# FM33A0XXX register map
File version: 1.0
CPU: SC000 r1p0, little endian, MPU, no FPU, 3 interrupt priority bits
Registers are 32-bit, read-write, reset 0x0 unless marked. A register's access mark holds for its fields unless they carry their own. Offsets are from the block's base; [hi:lo] are bit positions.

## PMU — POWER MANAGEMENT UNIT
Base 0x40000100
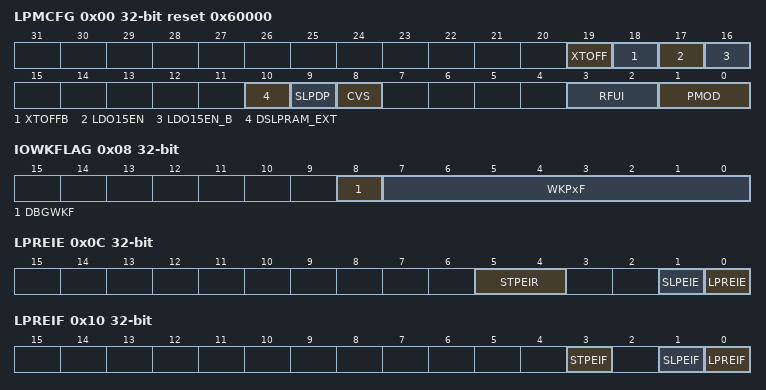
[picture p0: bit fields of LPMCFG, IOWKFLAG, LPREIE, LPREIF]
0x00 LPMCFG ro reset 0x60000 — Low Power Management Config Register
  [19] XTOFF rw — XTOFF BIT
    0=ENABLE (XTLF ENABLE); 1=DISABLE (XTLF DISABLE)
  [18] XTOFFB rw — XTOFFB BIT REVERSE
    0=XTLF CLOSE; 1=XTLF ENABLE
  [17] LDO15EN — LDO15 enable status
    0=DISABLE (LDO15 SHUT DOWN); 1=ENABLE (LDO15 ENABLE)
  [16] LDO15EN_B — LDO15 ENABLE BIT REVERSE
    0=ENABLE (ldo15 enable); 1=shutdown (ldo15 shutdown)
  [10] DSLPRAM_EXT rw — RAM status at deepsleep mode
    0=Alive (ram alive at deepsleep); 1=RAM_SHUTDOWN (RAM shutdown at deepsleep)
  [9] SLPDP rw — DeepSleep config
    0=Sleep mode; 1=DeepSleep mode,close vref
  [8] CVS rw — Core Voltage Scaling
    0=NOScaling (NOT Scaling at Sleep/DeepSleep/Stop mode); 1=Scaling to 1.2V at Sleep/DeepSleep/Stop mode
  [3:2] RFUI rw
  [1:0] PMOD rw — power down mode
    0=Active mode; 1=LPRUN mode; 2=Sleep mode; 3=Stop mode
0x04 WKDLYCON reset 0x1 — Wakeup Delay Control Register
  [1:0] TRHR — TIME OF RHR AT DeepSleep/Stop
    0=12us (time of RHR is 12us); 1=16us (time of RHR is 16us); 2=24us (time of RHR is 24us); 3=32us (time of RHR is 32us)
0x08 IOWKFLAG — IO Wakeup FLAG Register
  [8] DBGWKF — debug wakeup flag,write 1 to clear
    0=NODBWK (no debug wakeup); 1=DBWK (debug wakeup)
  [7:0] WKPxF — wakeup flag of pinX
0x0C LPREIE — low power IE register
  [5:4] STPEIR — stop error interrupt enable bit
    0=DISABLE (disable stop error interupt); 1=ENABLE (stop error interrupt enable)
  [1] SLPEIE — sleep error interrupt enable bit
    0=DISABLE (disable Sleep error interrupt); 1=ENABLE (Enable sleep error interrupt)
  [0] LPREIE — low power run error interrupt enable bit
    0=DISABLE (Disable lprun error interrupt); 1=ENABLE (Enable lprun error interrupt)
0x10 LPREIF — low power interrupt flag register
  [3] STPEIF — go into stop mode error flag
    0=STOP_OK (go into stop mode ok); 1=STOP_ERR (go into stop mode error)
  [1] SLPEIF — go into sleep mode error
    0=SLEEP_OK (go into sleep mode ok); 1=SLEEP_ERR (go into sleep mode error)
  [0] LPREIF — lprun error
    0=LPRUN_OK (go into lprun mode ok); 1=LPRUN_ERR (go into lprun mode error)

## HSPI — High speed SPI
Base 0x40000800
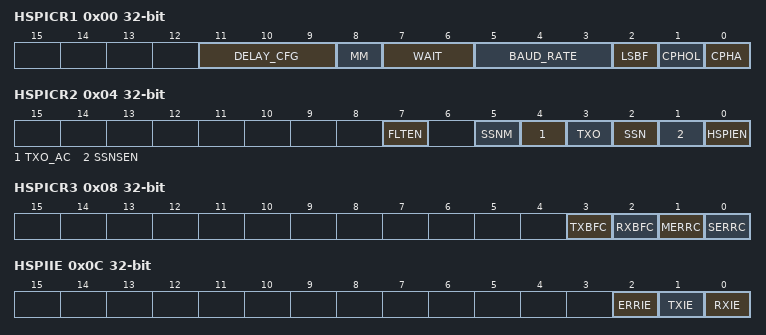
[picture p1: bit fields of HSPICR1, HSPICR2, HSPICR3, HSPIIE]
0x00 HSPICR1 — HSPI Control Register
  [11:9] DELAY_CFG — DELAY time setting for master sample delay /slave sending ahead
    0=NO_DELAY/NO_AHEAD (NO_DELAY at master/NO_AHEAD at slave); 1=10NS/0.5SCK-20NS (10NS delay at master/0.5SCK-20NS ahead at slave); 2=20NS/0.5SCK-15NS (20NS delay at master/0.5SCK-15NS ahead at slave); 3=30NS/0.5SCK-10NS (30NS delay at master/0.5SCK-10NS ahead at slave); 4=40NS/0.5SCK-5NS (40NS delay at master/0.5SCK-5NS ahead at slave); 5=0.5SCK (0.5SCK delay at master/0.5SCK ahead at slave); 6=0.5SCK (0.5SCK delay at master/0.5SCK ahead at slave); 7=0.5SCK (0.5SCK delay at master/0.5SCK ahead at slave)
  [8] MM — Master/Slave mode select
    0=SLAVE (slave mode); 1=Master mode
  [7:6] WAIT — WAIT clock setting at master mode,(1+wait) clock
  [5:3] BAUD_RATE — BAUD_RATE setting
    0=fPCLK (only Master mode); 1=fPCLK/2 (only Master mode); 2=fPCLK/4 (only Master mode); 3=fPCLK/8 (only Master mode); 4=fPCLK/16 (only Master mode); 5=fPCLK/32 (only Master mode); 6=fPCLK/64 (only Master mode); 7=fPCLK/128 (only Master mode)
  [2] LSBF — Frame format bit
    0=MSB (MSB first); 1=LSB (LSB first)
  [1] CPHOL — Clock polarity bit
    0=LOW (Idle clock voltage is low); 1=HIGH (Idle clock voltage is low)
  [0] CPHA — Clock phase bit
    0=FIRST (capture at First edge); 1=SECOND (capture at Second edge)
0x04 HSPICR2 — control Register2
  [7] FLTEN — filter enable for SSN/SCK/MOSI pad
    0=NO_FILTER (no filter for pad input); 1=4NS (filter 4ns for SSN/SCK/MOSI pad)
  [5] SSNM — SSN keep low/high after sending 8bit data at master mode
    0=LOW (SSN keep low after sending 8bit data at master mode); 1=HIGH (SSN keep hign after sending 8bit data at master mode)
  [4] TXO_AC — auto clear at tx_only mode enable
    0=DISABLE (disable auto clear at tx_only mode enable); 1=ENABLE (enable auto clear at tx_only mode enable)
  [3] TXO — TX only
    0=DISABLE (disable tx_only mode); 1=ENABLE (enable tx_only mode)
  [2] SSN — SSN control bit
    0=LOW (SSN output is low voltage); 1=HIGH (SSN output is high voltage)
  [1] SSNSEN — SSN controled by software at master mode
    0=AUTO_OUTPUT (SSN auto output at master mode); 1=SOFTWARE (SSN output controled by software at master mode)
  [0] HSPIEN — HSPI enable bit
    0=DISABLE (HSPI disable); 1=ENABLE (HSPI enable)
0x08 HSPICR3 — control Register3
  [3] TXBFC — Transmit Buffer Clear bit,write 1 to clear
  [2] RXBFC — Receive Buffer Clear bit,write 1 to clear
  [1] MERRC — Master Error Clear bit,write 1 to clear
  [0] SERRC — Slave Error Clear bit,write 1 to clear
0x0C HSPIIE — HSPI interrupt enable Register
  [2] ERRIE — error interrupt enable bit
  [1] TXIE — transmit interrupt enable bit
  [0] RXIE — receive interrupt enable bit
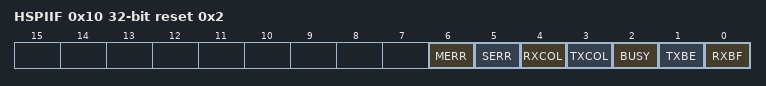
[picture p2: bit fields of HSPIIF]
0x10 HSPIIF reset 0x2 — HSPI interrupt flag Register
  [6] MERR ro — Master Error
  [5] SERR ro — Slave Error
  [4] RXCOL — RX Buffer overflow,write 1 to clear
  [3] TXCOL — TX Buffer overflow,write 1 to clear
  [2] BUSY ro — HSPI transmit flag
  [1] TXBE ro — TX Buffer Empty,write TXBUF clear this bit
  [0] RXBF ro — RX Buffer Full,read RXBUF clear this bit
0x14 HSPITXBUF — HSPI TX buffer Register
  [7:0] TXBUF — TXBUF 8BIT
0x18 HSPIRXBUF — HSPI RX buffer Register
  [7:0] RXBUF — RXBUF 8bit
